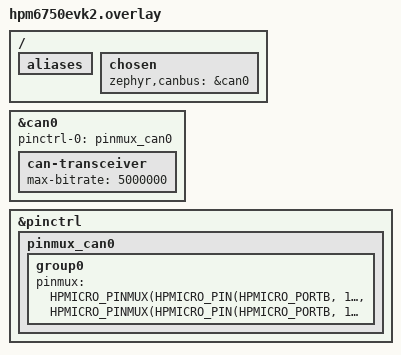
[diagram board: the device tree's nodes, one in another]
/*
 * Copyright 2024 HPMicro
 * SPDX-License-Identifier: Apache-2.0
 */

/ {
    aliases {
    };
    chosen {
        zephyr,canbus = &can0;
    };

};
&can0 {
    status = "okay";
    pinctrl-0 = <&pinmux_can0>;
    pinctrl-names = "default";
        can-transceiver {
        max-bitrate = <5000000>;
    };
};
&pinctrl {
    pinmux_can0: pinmux_can0 {
        group0 {
            pinmux = <HPMICRO_PINMUX(HPMICRO_PIN(HPMICRO_PORTB, 15), IOC_TYPE_IOC, 0, 7)>,
                     <HPMICRO_PINMUX(HPMICRO_PIN(HPMICRO_PORTB, 17), IOC_TYPE_IOC, 0, 7)>;
        };
    };
};

